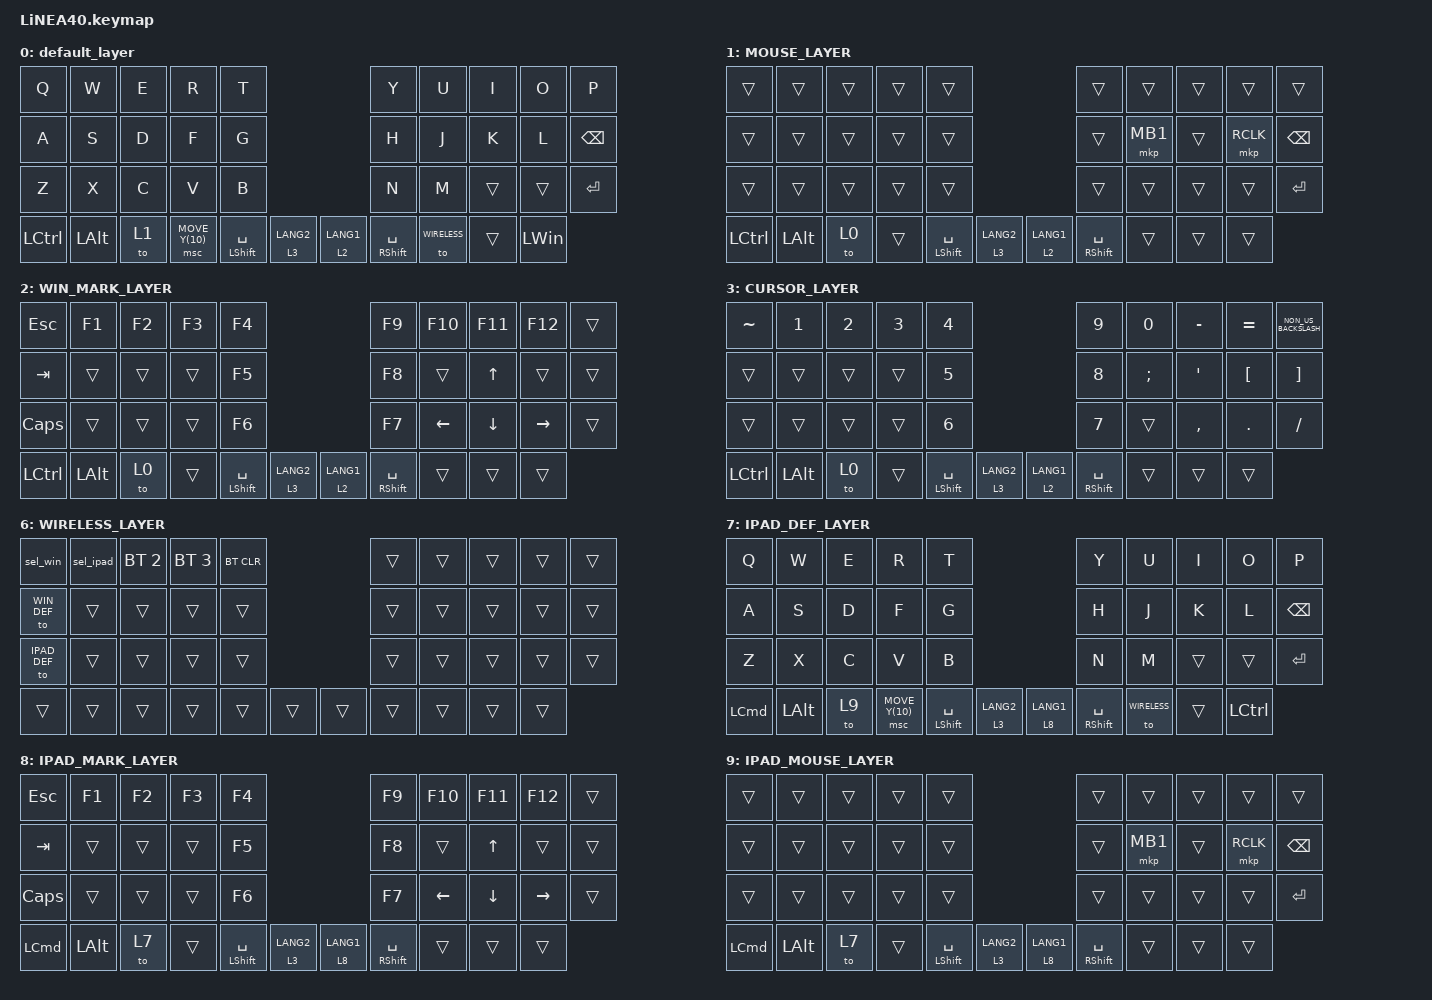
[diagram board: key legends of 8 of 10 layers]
#define ZMK_POINTING_DEFAULT_SCRL_VAL 150

#include <dt-bindings/zmk/input_transform.h>
#include <input/processors.dtsi>
#include <zephyr/dt-bindings/input/input-event-codes.h>
#include <behaviors.dtsi>
#include <dt-bindings/zmk/keys.h>
#include <dt-bindings/zmk/pointing.h>
#include <dt-bindings/zmk/bt.h>

#define WIN_DEF 0
#define MOUSE 1
#define WIN_MARK 2
#define CURSOR 3
#define FUNCTION 4
#define SCROLL 5
#define WIRELESS 6
#define IPAD_DEF 7
#define IPAD_MARK 8
#define IPAD_MOUSE 9

// mouse cursor
&mmv {
    delay-ms = <20>;
    trigger-period-ms = <5>;
    time-to-max-speed-ms = <100>;
    acceleration-exponent = <2>;
};

// mouse scroll
&msc {
    delay-ms = <3>;
    trigger-period-ms = <3>;
    time-to-max-speed-ms = <100>;
    acceleration-exponent = <0>;
};

/ {
    input_processors {
        zip_wheel_scaler: zip_wheel_scaler {
            compatible = "zmk,input-processor-scaler";
            #input-processor-cells = <2>;
            type = <INPUT_EV_REL>;
            codes = <INPUT_REL_WHEEL>;
            track-remainders;
        };
    };

    // マクロ定義: BT切替とレイヤー変更を同期
    macros {
        sel_win: sel_win {
            compatible = "zmk,behavior-macro";
            #binding-cells = <0>;
            bindings = <&bt BT_SEL 0>, <&to WIN_DEF>;
        };
        sel_ipad: sel_ipad {
            compatible = "zmk,behavior-macro";
            #binding-cells = <0>;
            bindings = <&bt BT_SEL 1>, <&to IPAD_DEF>;
        };
    };

    combos {
        compatible = "zmk,combos";
        ZenkakuHankaku { bindings = <&kp GRAVE>; key-positions = <11 12>; };
        DeleteKey { bindings = <&kp DEL>; key-positions = <7 8>; };
        InsertKey { bindings = <&kp INS>; key-positions = <6 7>; };
        CenterClick { bindings = <&mkp MB3>; key-positions = <17 16>; };
        RightClick { bindings = <&mkp MB2>; key-positions = <18 17>; };
        PrevClick { bindings = <&mkp MB4>; key-positions = <27 28>; };
        ClickNext { bindings = <&mkp MB5>; key-positions = <26 27>; };
    };

    behaviors {
        re_kp: sensor_rotate_kp {
            compatible = "zmk,behavior-sensor-rotate-var";
            #sensor-binding-cells = <2>;
            bindings = <&kp>, <&kp>;
        };
        mouse_scrl: mouse_wheel_scrl {
            compatible = "zmk,behavior-sensor-rotate-var";
            #sensor-binding-cells = <2>;
            bindings = <&msc>, <&msc>;
            tap-ms = <20>;
        };
    };

    keymap {
        compatible = "zmk,keymap";

        // 0: Windows Default
        default_layer {
            bindings = <
&kp Q      &kp W      &kp E  &kp R            &kp T                                           &kp Y                  &kp U  &kp I   &kp O   &kp P
&kp A      &kp S      &kp D  &kp F            &kp G                                           &kp H                  &kp J  &kp K   &kp L   &kp BACKSPACE
&kp Z      &kp X      &kp C  &kp V            &kp B                                           &kp N                  &kp M  &trans  &trans  &kp ENTER
&kp LCTRL  &kp LALT   &to 1  &msc MOVE_Y(10)  &mt LSHIFT SPACE  &lt 3 LANG2    &lt 2 LANG1  &mt RIGHT_SHIFT SPACE  &to WIRELESS &trans  &kp LEFT_WIN
>;
            sensor-bindings = <&mouse_scrl SCRL_DOWN SCRL_UP>;
        };

        // 1: MOUSE
        MOUSE_LAYER {
            bindings = <
&trans     &trans        &trans  &trans  &trans                                            &trans                  &trans    &trans  &trans     &trans
&trans     &trans        &trans  &trans  &trans                                            &trans                  &mkp MB1  &trans  &mkp RCLK  &kp BACKSPACE
&trans     &trans        &trans  &trans  &trans                                            &trans                  &trans    &trans  &trans     &kp ENTER
&kp LCTRL  &kp LEFT_ALT  &to 0   &trans  &mt LEFT_SHIFT SPACE  &lt 3 LANG2    &lt 2 LANG1  &mt RIGHT_SHIFT SPACE  &trans    &trans  &trans
>;
        };

        // 2: Windows MARK
        WIN_MARK_LAYER {
            bindings = <
&kp ESC       &kp F1        &kp F2  &kp F3  &kp F4                                        &kp F9                  &kp F10         &kp F11       &kp F12    &trans
&kp TAB       &trans        &trans  &trans  &kp F5                                        &kp F8                  &trans          &kp UP_ARROW  &trans     &trans
&kp CAPSLOCK  &trans        &trans  &trans  &kp F6                                        &kp F7                  &kp LEFT_ARROW  &kp DOWN      &kp RIGHT  &trans
&kp LCTRL     &kp LEFT_ALT  &to 0   &trans  &mt LSHIFT SPACE  &lt 3 LANG2    &lt 2 LANG1  &mt RIGHT_SHIFT SPACE  &trans          &trans        &trans
>;
            sensor-bindings = <&re_kp LC(MINUS) LC(PLUS)>;
        };

        // 3: CURSOR
        CURSOR_LAYER {
            bindings = <
&kp TILDE  &kp NUMBER_1  &kp NUMBER_2  &kp NUMBER_3  &kp NUMBER_4                                        &kp NUMBER_9           &kp NUMBER_0   &kp MINUS  &kp EQUAL         &kp NON_US_BACKSLASH
&trans     &trans        &trans        &trans        &kp NUMBER_5                                        &kp NUMBER_8           &kp SEMICOLON  &kp SQT    &kp LEFT_BRACKET  &kp RIGHT_BRACKET
&trans     &trans        &trans        &trans        &kp NUMBER_6                                        &kp NUMBER_7           &trans         &kp COMMA  &kp PERIOD        &kp SLASH
&kp LCTRL  &kp LEFT_ALT  &to 0         &trans        &mt LEFT_SHIFT SPACE  &lt 3 LANG2    &lt 2 LANG1  &mt RIGHT_SHIFT SPACE  &trans         &trans     &trans
>;
            sensor-bindings = <&re_kp LC(MINUS) LC(PLUS)>;
        };

        FUNCTION_LAYER { bindings = <&none &none &none &none &none &none &none &none &none &none &none &none &none &none &none &none &none &none &none &none &none &none &none &none &none &none &none &none &none &none &none &none &none &none &none &none &none &none &none &none &none &none &none &none>; };
        SCROLL_LAYER { bindings = <&none &none &none &none &none &none &none &none &none &none &none &none &none &none &none &none &none &none &none &none &none &none &none &none &none &none &none &none &none &none &none &none &none &none &none &none &none &none &none &none &none &none &none &none>; };

        // 6: WIRELESS
        WIRELESS_LAYER {
            bindings = <
&sel_win     &sel_ipad    &bt BT_SEL 2 &bt BT_SEL 3 &bt BT_CLR               &trans &trans &trans &trans &trans
&to WIN_DEF  &trans        &trans        &trans        &trans                   &trans &trans &trans &trans &trans
&to IPAD_DEF &trans        &trans        &trans        &trans                   &trans &trans &trans &trans &trans
&trans       &trans        &trans        &trans        &trans &trans    &trans  &trans &trans &trans &trans
>;
        };

        // 7: iPad Default
        IPAD_DEF_LAYER {
            bindings = <
&kp Q      &kp W      &kp E  &kp R            &kp T                                           &kp Y                  &kp U  &kp I   &kp O   &kp P
&kp A      &kp S      &kp D  &kp F            &kp G                                           &kp H                  &kp J  &kp K   &kp L   &kp BACKSPACE
&kp Z      &kp X      &kp C  &kp V            &kp B                                           &kp N                  &kp M  &trans  &trans  &kp ENTER
&kp LCMD   &kp LALT   &to 9  &msc MOVE_Y(10)  &mt LSHIFT SPACE  &lt 3 LANG2    &lt 8 LANG1  &mt RIGHT_SHIFT SPACE  &to WIRELESS &trans  &kp LCTRL
>;
            sensor-bindings = <&mouse_scrl SCRL_DOWN SCRL_UP>;
        };

        // 8: iPad MARK
        IPAD_MARK_LAYER {
            bindings = <
&kp ESC       &kp F1        &kp F2  &kp F3  &kp F4                                        &kp F9                  &kp F10         &kp F11       &kp F12    &trans
&kp TAB       &trans        &trans  &trans  &kp F5                                        &kp F8                  &trans          &kp UP_ARROW  &trans     &trans
&kp CAPSLOCK  &trans        &trans  &trans  &kp F6                                        &kp F7                  &kp LEFT_ARROW  &kp DOWN      &kp RIGHT  &trans
&kp LCMD      &kp LEFT_ALT  &to 7   &trans  &mt LSHIFT SPACE  &lt 3 LANG2    &lt 8 LANG1  &mt RIGHT_SHIFT SPACE  &trans          &trans        &trans
>;
            sensor-bindings = <&re_kp LG(MINUS) LG(PLUS)>;
        };

        // 9: iPad MOUSE (iPad専用の自動切り替え先)
        IPAD_MOUSE_LAYER {
            bindings = <
&trans     &trans        &trans  &trans  &trans                                            &trans                  &trans    &trans  &trans     &trans
&trans     &trans        &trans  &trans  &trans                                            &trans                  &mkp MB1  &trans  &mkp RCLK  &kp BACKSPACE
&trans     &trans        &trans  &trans  &trans                                            &trans                  &trans    &trans  &trans     &kp ENTER
&kp LCMD   &kp LEFT_ALT  &to 7   &trans  &mt LEFT_SHIFT SPACE  &lt 3 LANG2    &lt 8 LANG1  &mt RIGHT_SHIFT SPACE  &trans    &trans  &trans
>;
        };
    };
};

&msc_input_listener {
    speed_up {
        layers = <FUNCTION>;
        input-processors = <&zip_wheel_scaler 3 1>; 
    };
};

&trackball_listener {
    automouse_ipad {
        layers = <IPAD_DEF>;
        input-processors = <&zip_temp_layer IPAD_MOUSE 1000>;
    };

    scroller {
        layers = <SCROLL>;
        input-processors =
            <&zip_xy_transform INPUT_TRANSFORM_Y_INVERT>,
            <&zip_xy_to_scroll_mapper>;
    };
};
